AUTOSAR XML (schema 4-0-3)
package /ComponentTypes
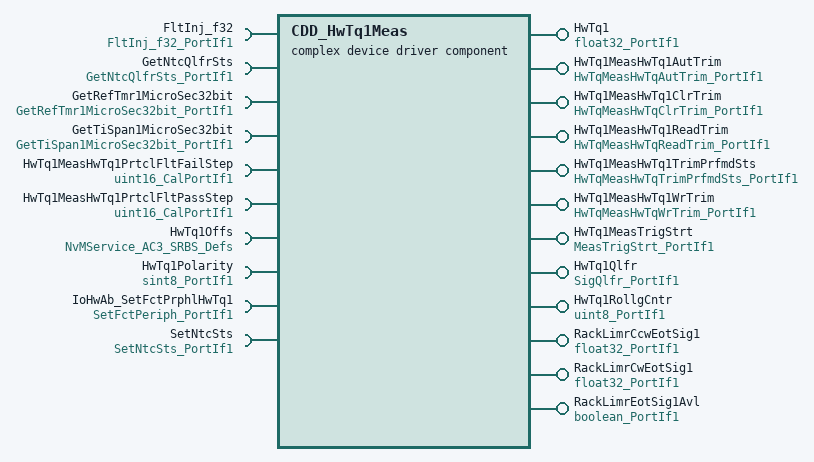
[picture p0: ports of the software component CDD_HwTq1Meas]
  complex device driver sw component type CDD_HwTq1Meas
    12 x provide port:
      HwTq1: nonqueued-sender-com-spec{data-element=Val, init-value=0}, provided-interface=float32_PortIf1
      HwTq1MeasHwTq1AutTrim: server-com-spec{operation=Oper, queue-length=1}, provided-interface=HwTqMeasHwTqAutTrim_PortIf1
      HwTq1MeasHwTq1ClrTrim: server-com-spec{operation=Oper, queue-length=1}, provided-interface=HwTqMeasHwTqClrTrim_PortIf1
      HwTq1MeasHwTq1ReadTrim: server-com-spec{operation=Oper, queue-length=1}, provided-interface=HwTqMeasHwTqReadTrim_PortIf1
      HwTq1MeasHwTq1TrimPrfmdSts: server-com-spec{operation=Oper, queue-length=1}, provided-interface=HwTqMeasHwTqTrimPrfmdSts_PortIf1
      HwTq1MeasHwTq1WrTrim: server-com-spec{operation=Oper, queue-length=1}, provided-interface=HwTqMeasHwTqWrTrim_PortIf1
      HwTq1MeasTrigStrt: server-com-spec{operation=Oper, queue-length=1}, provided-interface=MeasTrigStrt_PortIf1
      HwTq1Qlfr: nonqueued-sender-com-spec{data-element=Val, init-value=0}, provided-interface=SigQlfr_PortIf1
      HwTq1RollgCntr: nonqueued-sender-com-spec{data-element=Val, init-value=0}, provided-interface=uint8_PortIf1
      RackLimrCcwEotSig1: nonqueued-sender-com-spec{data-element=Val, init-value=0}, provided-interface=float32_PortIf1
      RackLimrCwEotSig1: nonqueued-sender-com-spec{data-element=Val, init-value=0}, provided-interface=float32_PortIf1
      RackLimrEotSig1Avl: nonqueued-sender-com-spec{data-element=Logl, init-value=0}, provided-interface=boolean_PortIf1
    10 x require port:
      FltInj_f32: client-com-spec=Oper, required-interface=FltInj_f32_PortIf1
      GetNtcQlfrSts: client-com-spec=Oper, required-interface=GetNtcQlfrSts_PortIf1
      GetRefTmr1MicroSec32bit: client-com-spec=Oper, required-interface=GetRefTmr1MicroSec32bit_PortIf1
      GetTiSpan1MicroSec32bit: client-com-spec=Oper, required-interface=GetTiSpan1MicroSec32bit_PortIf1
      HwTq1MeasHwTq1PrtclFltFailStep: parameter-require-com-spec{init-value=2521, parameter=Val}, required-interface=uint16_CalPortIf1
      HwTq1MeasHwTq1PrtclFltPassStep: parameter-require-com-spec{init-value=1000, parameter=Val}, required-interface=uint16_CalPortIf1
      HwTq1Offs: required-com-specs=[EraseBlock, GetErrorStatus, InvalidateNvBlock, ReadBlock, RestoreBlockDefaults, SetRamBlockStatus, WriteBlock], required-interface=NvMService_AC3_SRBS_Defs
      HwTq1Polarity: nonqueued-receiver-com-spec{data-element=Val, filter=data-filter-type=ALWAYS, init-value=1}, required-interface=sint8_PortIf1
      IoHwAb_SetFctPrphlHwTq1: client-com-spec=Oper, required-interface=SetFctPeriph_PortIf1
      SetNtcSts: client-com-spec=Oper, required-interface=SetNtcSts_PortIf1
    behavior CDD_HwTq1Meas_InternalBehavior: port-api-option{enable-take-address=false, indirect-api=false, port=FltInj_f32}
      ar-typed-per-instance-memorys:
        15 x data, all with sw-calibration-access=READ-ONLY:
          HwTq1ComStsErrCntr: type=uint8
          HwTq1IntSnsrErrCntr: type=uint8
          HwTq1MeasPrevHwTq1: type=float32
          HwTq1MeasPrevRollgCntr: type=uint8
          HwTq1MsgMissRxCnt: type=uint32
          HwTq1Offs: type=HwTqOffsRec1
          RackLimrCcwEot1: type=float32
          RackLimrCwEot1: type=float32
          RackLimrEot1Avl: type=boolean
          RackLimrEot1Data{0..2}: type=uint8
          RackLimrEot1Id{2..4}DataReadCmpl: type=boolean
      5 x operation invoked event:
        OIT_HwTq1MeasHwTq1AutTrim_Oper_HwTq1MeasHwTq1AutTrim_Oper: start-on-event=HwTq1MeasHwTq1AutTrim_Oper, operation=HwTq1MeasHwTq1AutTrim.Oper
        OIT_HwTq1MeasHwTq1ClrTrim_Oper_HwTq1MeasHwTq1ClrTrim_Oper: start-on-event=HwTq1MeasHwTq1ClrTrim_Oper, operation=HwTq1MeasHwTq1ClrTrim.Oper
        OIT_HwTq1MeasHwTq1ReadTrim_Oper_HwTq1MeasHwTq1ReadTrim_Oper: start-on-event=HwTq1MeasHwTq1ReadTrim_Oper, operation=HwTq1MeasHwTq1ReadTrim.Oper
        OIT_HwTq1MeasHwTq1TrimPrfmdSts_Oper_HwTq1MeasHwTq1TrimPrfmdSts_Oper: start-on-event=HwTq1MeasHwTq1TrimPrfmdSts_Oper, operation=HwTq1MeasHwTq1TrimPrfmdSts.Oper
        OIT_HwTq1MeasHwTq1WrTrim_Oper_HwTq1MeasHwTq1WrTrim_Oper: start-on-event=HwTq1MeasHwTq1WrTrim_Oper, operation=HwTq1MeasHwTq1WrTrim.Oper
      4 x timing event:
        HwTq1MeasInit1_InitEvent: start-on-event=HwTq1MeasInit1, period=0
        TMT_HwTq1MeasPer1: start-on-event=HwTq1MeasPer1, period=0.002
        TMT_HwTq1MeasPer3: start-on-event=HwTq1MeasPer2, period=0.1
        TMT_HwTq1MeasPer3Stub: start-on-event=HwTq1MeasPer3Stub, period=0.002
      operation invoked event OIT_HwTq1MeasTrigStrt_Oper_HwTq1MeasTrgStrt_Oper: start-on-event=HwTq1MeasTrigStrt_Oper, operation=HwTq1MeasTrigStrt.Oper
      10 x runnable:
        HwTq1MeasHwTq1AutTrim_Oper
          sync call SC_HwTq1Offs_SetRamBlockStatus: operation=HwTq1Offs.SetRamBlockStatus, timeout=0
        HwTq1MeasHwTq1ClrTrim_Oper
          sync call SC_HwTq1Offs_SetRamBlockStatus: operation=HwTq1Offs.SetRamBlockStatus, timeout=0
        HwTq1MeasHwTq1ReadTrim_Oper
        HwTq1MeasHwTq1TrimPrfmdSts_Oper
        HwTq1MeasHwTq1WrTrim_Oper
          sync call SC_HwTq1Offs_SetRamBlockStatus: operation=HwTq1Offs.SetRamBlockStatus, timeout=0
        HwTq1MeasInit1
          sync call SC_GetRefTmr1MicroSec32bit_Oper: operation=GetRefTmr1MicroSec32bit.Oper, timeout=0
          sync call SC_GetTiSpan1MicroSec32bit_Oper: operation=GetTiSpan1MicroSec32bit.Oper, timeout=0
          sync call SC_IoHwAb_SetFctPrphlHwTq1_Oper: operation=IoHwAb_SetFctPrphlHwTq1.Oper, timeout=0
        HwTq1MeasPer1
          data-receive-point-by-arguments:
            access REC_HwTq0Polarity_Val: accessed-variable=HwTq1Polarity.Val
          data-send-points:
            6 x access:
              SEND_HwTq0_Val: accessed-variable=HwTq1.Val
              SEND_HwTq0Qlfr_Val: accessed-variable=HwTq1Qlfr.Val
              SEND_HwTq0RollgCntr_Val: accessed-variable=HwTq1RollgCntr.Val
              SEND_RackLimrCcwEotSig1_Val: accessed-variable=RackLimrCcwEotSig1.Val
              SEND_RackLimrCwEotSig1_Val: accessed-variable=RackLimrCwEotSig1.Val
              SEND_RackLimrEotSig1Avl_Logl: accessed-variable=RackLimrEotSig1Avl.Logl
          sync call SC_FltInj_f32_Oper: operation=FltInj_f32.Oper, timeout=0
          sync call SC_GetNtcQlfrSts_Oper: operation=GetNtcQlfrSts.Oper, timeout=0
          sync call SC_SetNtcSts_Oper: operation=SetNtcSts.Oper, timeout=0
        HwTq1MeasPer2
          sync call SC_SetNtcSts_Oper: operation=SetNtcSts.Oper, timeout=0
        HwTq1MeasPer3Stub
        HwTq1MeasTrigStrt_Oper
          sync call SC_GetRefTmr1MicroSec32bit_Oper: operation=GetRefTmr1MicroSec32bit.Oper, timeout=0
          sync call SC_GetTiSpan1MicroSec32bit_Oper: operation=GetTiSpan1MicroSec32bit.Oper, timeout=0
      swc service dependency NvmHwTq1Offs: assigned-datas=[{role=ramBlock, used-data-element=HwTq1Offs}, {role=defaultValue, used-parameter-element=HwTq1OffsDft}], assigned-ports=role-based-port-assignment={port-prototype=HwTq1Offs, role=NvMService_AC3_SRBS_Defs}
        service-needs:
          nv block needs NvmHwTq1Offs: n-data-sets=0, readonly=false, reliability=ERROR-DETECTION, resistant-to-changed-sw=true, restore-at-start=true, store-at-shutdown=true, write-only-once=false, writing-frequency=0, writing-priority=LOW
      shared-parameters:
        parameter data prototype HwTq1OffsDft: sw-calibration-access=READ-WRITE, type=HwTqOffsRec1, init-value=fields=[OffsTrim:0, OffsTrimPrfmdSts:0]
  swc implementation CDD_HwTq1Meas_Implementation: behavior=CDD_HwTq1Meas_InternalBehavior
    code-descriptors:
      code Default: artifact-descriptors=autosar-engineering-object={short-label=Default, category=SWSRC}
